# R7KA8P1AD register map
Vendor: Renesas Electronics Corporation; Series: RA8; File version: 1.10.02
CPU: CM85 r0p2, little endian, MPU, FPU, VTOR, 4 interrupt priority bits, 96 interrupts
Registers are 32-bit, read-write, reset 0x0 unless marked. A register's access mark holds for its fields unless they carry their own. Offsets are from the block's base; [hi:lo] are bit positions; {n}, {i} and the like mark numbered series; 'fields as' and 'values as' point back to an identical list.

## DRW — 2D Drawing Engine
Base 0x40444000
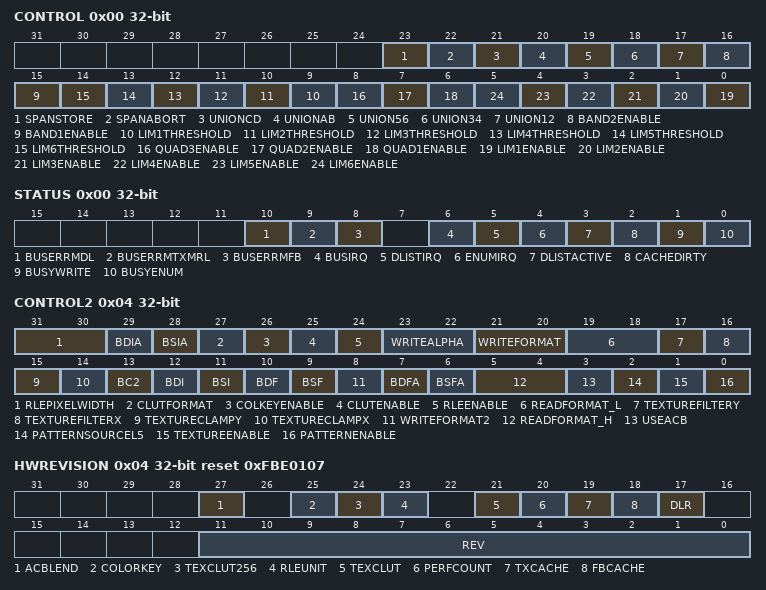
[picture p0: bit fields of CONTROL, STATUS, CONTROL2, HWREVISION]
0x00 CONTROL wo — Geometry Control Register
  [23] SPANSTORE
    0=Disable; 1=Enable. Next line span start is always equal to or left of the current line span start. See .
  [22] SPANABORT
    0=Disable; 1=Enable
  [21] UNIONCD — Combine Outputs C and D as Union
    0=Select minimum/intersect between limiters C and D; 1=Select maximum/union between limiters C and D. The output is final.
  [20] UNIONAB — Combine Outputs A and B as Union
    0=Select minimum/intersect between limiters A and B; 1=Select maximum/union between limiters A and B. The output is called C.
  [19] UNION56 — Combine Limiters 5 and 6 as Union
    0=Select minimum/intersect between limiters 5 and 6; 1=Select maximum/union between limiters 5 and 6. The output is called D.
  [18] UNION34 — Combine Limiters 3 and 4 as Union
    0=Select minimum/intersect between limiters 3 and 4; 1=Select maximum/union between limiters 3 and 4. The output is called B.
  [17] UNION12 — Combine Limiters 1 and 2 as Union
    0=Select minimum/intersect between limiters 1 and 2; 1=Select maximum/union between limiters 1 and 2. The output is called A.
  [16] BAND2ENABLE — Enable Band Post Process for Limiter 2
    0=Disable; 1=Enable
  [15] BAND1ENABLE — Enable Band Post Process for Limiter 1
    0=Disable; 1=Enable
  [n+8] LIM{n}THRESHOLD (n=1..6) — Enable Limiter {n} Threshold Mode
    0=Disable; 1=Enable
  [8] QUAD3ENABLE — Enable Quadratic Coupling of Limiters 5 and 6
    0=Disable; 1=Enable
  [7] QUAD2ENABLE — Enable Quadratic Coupling of Limiters 3 and 4
    0=Disable; 1=Enable
  [6] QUAD1ENABLE — Enable Quadratic Coupling of Limiters 1 and 2
    0=Disable; 1=Enable
  [n-1] LIM{n}ENABLE (n=1..6) — Enable Limiter {n}
    0=Disable; 1=Enable
0x00 STATUS ro (alternate view of CONTROL) — Status Control Register
  [10] BUSERRMDL — Display List Bus Error Interrupt Triggered
    0=No display list bus error occurred or interrupt disabled; 1=Display list bus error interrupt triggered
  [9] BUSERRMTXMRL — Texture Bus Error Interrupt Triggered
    0=No texture bus error occurred or interrupt disabled; 1=Texture bus error interrupt triggered
  [8] BUSERRMFB — Framebuffer Bus Error Interrupt Triggered
    0=No framebuffer bus error occurred or interrupt disabled; 1=Framebuffer bus error interrupt triggered
  [6] BUSIRQ — Bus Error Interrupt Triggered
    0=No bus error occurred or interrupt disabled; 1=Bus error interrupt triggered
  [5] DLISTIRQ — Display List Interrupt Triggered
    0=Display list not finished or interrupt disabled; 1=Display list finished interrupt triggered
  [4] ENUMIRQ — Enumeration Interrupt Triggered
    0=Enumeration not finished or interrupt disabled; 1=Enumeration finished interrupt triggered
  [3] DLISTACTIVE — Display List Reader Status
    0=Display list reader is idle; 1=Display list reader is busy, and no direct write access to registers allowed
  [2] CACHEDIRTY — Framebuffer Cache Status
    0=Framebuffer cache is not dirty; 1=Framebuffer cache is dirty, and frame should not be flipped
  [1] BUSYWRITE — Framebuffer Writeback Status
    0=Framebuffer writeback finished; 1=Framebuffer writeback busy, framebuffer type cannot be changed
  [0] BUSYENUM — Enumeration Unit Status
    0=Enumeration unit idle; 1=Enumeration unit is busy, new primitive cannot be started
0x04 CONTROL2 wo — Surface Control Register
  [31:30] RLEPIXELWIDTH — Texel Width for RLE Unit
    0=1 byte per texel; 1=2 bytes per texel; 2=3 bytes per texel; 3=4 bytes per texel
  [29] BDIA — Blend Destination Factor Inverted in Alpha Channel
    0=Use blend factor as specified through BDFA; 1=Invert destination blend factor (1-x)
  [28] BSIA — Blend Source Factor Inverted in Alpha Channel
    0=Use blend factor as specified through BSFA; 1=Invert blend source factor (1-x)
  [27] CLUTFORMAT
    0=Format CLUT as ARGB (8888); 1=Format CLUT as RGB (565)
  [26] COLKEYENABLE — Color Keying Enable
    0=Disable color keying; 1=Enable color keying
  [25] CLUTENABLE
    0=Disable CLUT; 1=Enable CLUT
  [24] RLEENABLE
    0=Disable RLE; 1=Enable RLE
  [23:22] WRITEALPHA — Writeback Alpha Source for Framebuffer
    0=(USEACB = 0) Use alpha from color 2 (USEACB = 0) (USEACB = 1) BC2A = 1: Use alpha in color 2 as destination (DST_A); 1=(USEACB = 0) Use source alpha (pixel coverage) (USEACB = 1) BC2A = 0: Use alpha from framebuffer as destination (DST_A); 2=(USEACB = 0) Use 0.0 as alpha (USEACB = 1) BC2A = 0: Use alpha from framebuffer as destination (DST_A); 2=(USEACB = 0) Use alpha from framebuffer (USEACB = 1) BC2A = 0: Use alpha from framebuffer as destination (DST_A)
  [21:20] WRITEFORMAT — Writeback Framebuffer Format
  [19:18] READFORMAT_L — Texture Format Descriptor
  [17] TEXTUREFILTERY — Linear Filtering on Texture V Axis
    0=No filtering on texture V axis; 1=Linear filtering on texture V axis
  [16] TEXTUREFILTERX — Linear Filtering on Texture U Axis
    0=No filtering on texture U axis; 1=Linear filtering on texture U axis
  [15] TEXTURECLAMPY — Calculating V Limiter Outside Used Texture
    0=Texture wrap mode: Integer part of the calculated value from the V limiter is AND gated with TEXVMASK, resulting in a repetition of texture in the y/v direction; 1=Texture clamp mode: Texture color at the border of the texture is taken, resulting in a repetition of texture border color in the y/v direction
  [14] TEXTURECLAMPX — Calculating U Limiter Outside Used Texture
    0=Texture wrap mode: Integer part of the calculated value from the U limiter is AND gated with TEXUMASK, resulting in a repetition of texture in the x/u direction; 1=Texture clamp mode: Texture color at the border of the texture is taken, resulting in a repetition of texture border color in the x/u direction
  [13] BC2 — Blend color 2
    0=Use pixel from framebuffer as destination (DST); 1=Use color 2 as destination (DST)
  [12] BDI — Blend Destination Factor Inverted
    0=Use blend factor as specified through BDF; 1=Invert blend destination factor (1-x)
  [11] BSI — Blend Source Factor Inverted
    0=Use blend factor as specified through BSF; 1=Invert blend source factor (1-x)
  [10] BDF — Blend Destination Factor
    0=Use 1.0 as blend destination factor; 1=Use alpha as blend destination factor
  [9] BSF — Blend Source Factor
    0=Use 1.0 as blend source factor; 1=Use alpha as blend source factor
  [8] WRITEFORMAT2 — Writeback Framebuffer Format
  [7] BDFA — Blend Destination Factor for Alpha Channel
    0=Use 1.0 as blend destination factor for alpha channel; 1=Use alpha as blend destination factor for alpha channel
  [6] BSFA — Blend Source Factor for Alpha Channel
    0=Use 1.0 as blend source factor for alpha channel; 1=Use alpha as blend source factor for alpha channel
  [5:4] READFORMAT_H — Texture Format Descriptor
  [3] USEACB — Alpha Blend Mode
    0=Use WRITEALPHA[1:0] mode; 1=Use full alpha channel blending mode
  [2] PATTERNSOURCEL5 — Limiter 5 Enable for Pattern Index
  [1] TEXTUREENABLE — Texture Enable for Pixel Source
    0=Disable texture; 1=Enable texture
  [0] PATTERNENABLE — Pattern Color Enable for Pixel Source
    0=Disable pattern; 1=Enable pattern
0x04 HWREVISION ro reset 0xFBE0107 (alternate view of CONTROL2) — Hardware Version and Feature Set ID Register
  [27] ACBLEND — Alpha Channel Blending Available
    0=Full alpha channel blending is not available; 1=Full alpha channel blending is available
  [25] COLORKEY — Color Key Available
    0=No color key; 1=Color key is available
  [24] TEXCLUT256 — Texture CLUT size
    0=Texture CLUT size is 16 entries; 1=Texture CLUT size is 256 entries
  [23] RLEUNIT — RLE Unit Available
    0=No RLE unit; 1=RLE unit is available
  [21] TEXCLUT — Texture CLUT Available
    0=No texture CLUT; 1=Texture CLUT is available
  [20] PERFCOUNT — Two Performance Counter Available
    0=No performance counter; 1=Tow performance counters available
  [19] TXCACHE — Texture Cache Available
    0=No texture cache; 1=Texture cache is available
  [18] FBCACHE — Framebuffer Cache Available
    0=No framebuffer cache; 1=Framebuffer cache is available
  [17] DLR — Display List Reader Available
    0=No display list reader; 1=Display list reader is available
  [11:0] REV — Revision Number of DRW is stored.
{0xC+4i} L{i}START (i=1..6) wo — Limiter {i} Start Value Register (n = 1 to 6)
  [31:0] LSTART — Start Value of the nth Limiter
{0x24+4i} L{i}XADD (i=1..6) wo — Limiter {i} X-Axis Increment Register(n = 1 to 6)
  [31:0] LXADD — X-Axis Increment
{0x3C+4i} L{i}YADD (i=1..6) wo — Limiter {i} Y-Axis Increment Register(n = 1 to 6)
  [31:0] LYADD — Y-Axis Increment
{0x54+4i} L{i}BAND (i=1..2) wo — Limiter m Band Width Parameter Register(n = 1, 2)
  [31:0] LBAND — Limiter m Band Width Parameter
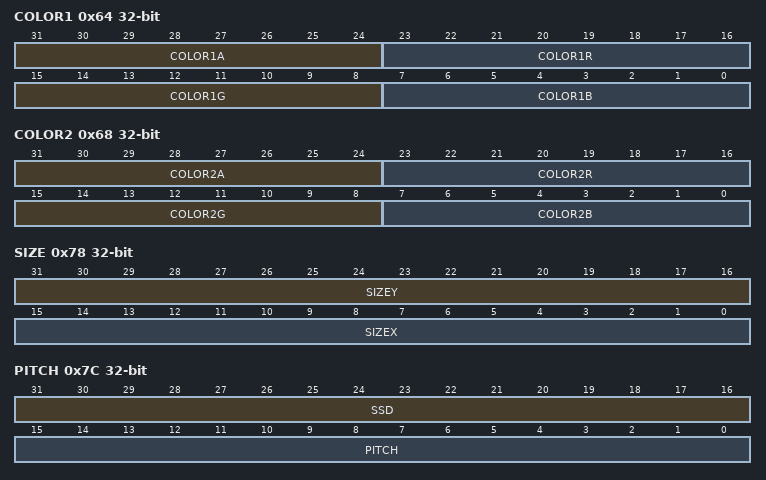
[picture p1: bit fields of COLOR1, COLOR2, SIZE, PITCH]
0x64 COLOR1 wo — Base Color Register
  [31:24] COLOR1A — Alpha Channel of Color 1
  [23:16] COLOR1R — Red Channel of Color 1
  [15:8] COLOR1G — Green Channel of Color 1
  [7:0] COLOR1B — Blue Channel of Color 1
0x68 COLOR2 wo — Secondary Color Register
  [31:24] COLOR2A — Alpha Channel of Color 2
  [23:16] COLOR2R — Red Channel of Color 2
  [15:8] COLOR2G — Green Channel of Color 2
  [7:0] COLOR2B — Blue Channel of Color 2
0x74 PATTERN wo
  [7:0] PATTERN — Bitmap of the Pattern
0x78 SIZE wo — Bounding Box Dimension Register
  [31:16] SIZEY — Bounding Box Height
  [15:0] SIZEX — Bounding Box Width
0x7C PITCH wo — Framebuffer Pitch And Spanstore Delay Register
  [31:16] SSD — Spanstore Delay
  [15:0] PITCH — Pitch of the Framebuffer
0x80 ORIGIN wo — Framebuffer Base Address Register
  [31:0] ORIGIN — Address of the First Pixel in Framebuffer
0x90 LUSTART wo — U Limiter Start Value Register
  [31:0] LUSTART — U Limiter Start Value
0x94 LUXADD wo — U Limiter X-Axis Increment Register
  [31:0] LUXADD — U Limiter X-Axis Increment
0x98 LUYADD wo — U Limiter Y-Axis Increment Register
  [31:0] LUYADD — U Limiter Y-Axis Increment
0x9C LVSTARTI wo — V Limiter Start Value Integer Part Register
  [0] LVSTARTI — V Limiter Start Value Integer Part
0xA0 LVSTARTF wo — V Limiter Start Value Fractional Part Register
  [15:0] LVSTARTF — V Limiter Start Value Fractional Part
0xA4 LVXADDI wo — V Limiter X-Axis Increment Integer Part Register
  [31:0] LVXADDI — V Limiter X-Axis Increment Integer Part
0xA8 LVYADDI wo — V Limiter Y-Axis Increment Integer Part Register
  [31:0] LVYADDI — V Limiter Y-Axis Increment Integer Part
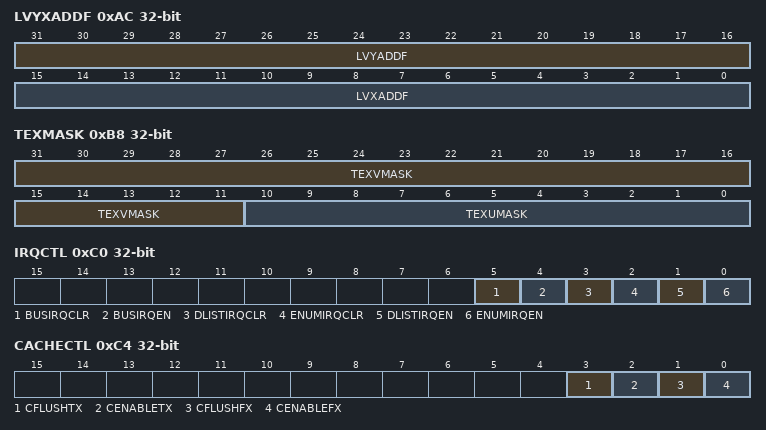
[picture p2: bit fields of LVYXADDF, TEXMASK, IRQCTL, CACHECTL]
0xAC LVYXADDF wo — V Limiter Increment Fractional Parts Register
  [31:16] LVYADDF — V Limiter Y-Axis Increment Fractional Part
  [15:0] LVXADDF — V Limiter X-Axis Increment Fractional Part
0xB4 TEXPITCH wo — Texels Per Texture Line Register
  [31:0] TEXPITCH — Texels Per Texture Line
0xB8 TEXMASK wo — Texture Size or Texture Address Mask Register
  [31:11] TEXVMASK — V Mask in Texture Mode
  [10:0] TEXUMASK — U Mask in Texture Mode
0xBC TEXORIGIN wo — Texture Base Address Register
  [31:0] TEXORIGIN — Texture Base Address
0xC0 IRQCTL wo — Interrupt Control Register
  [5] BUSIRQCLR — Clear BUSIRQ
    0=Do not clear BUSIRQ bus error interrupt; 1=Clear BUSIRQ bus error interrupt
  [4] BUSIRQEN — BUSIRQ Interrupt Mask Enable
    0=Disable (mask) BUSIRQ bus error interrupt; 1=Enable (unmask) BUSIRQ bus error interrupt
  [3] DLISTIRQCLR — Clear DLISTIRQ
    0=Do not clear DLISTIRQ display list interrupt; 1=Clear DLISTIRQ display list interrupt
  [2] ENUMIRQCLR — Clear ENUMIRQ
    0=Do not clear ENUMIRQ enumeration interrupt; 1=Clear ENUMIRQ enumeration interrupt
  [1] DLISTIRQEN — DLISTIRQ Interrupt Mask Enable
    0=Disable (mask) DLISTIRQ display list interrupt; 1=Enable (unmask) DLISTIRQ display list interrupt
  [0] ENUMIRQEN — ENUMIRQ Interrupt Mask Enable
    0=Disable (mask) ENUMIRQ enumeration interrupt; 1=Enable (unmask) ENUMIRQ enumeration interrupt
0xC4 CACHECTL wo — Cache Control Register
  [3] CFLUSHTX — Flush Texture Cache
    0=Do not flush the texture cache; 1=Flush the texture cache
  [2] CENABLETX — Texture Cache Enable
    0=Disable the texture cache; 1=Enable the texture cache
  [1] CFLUSHFX — Flush Framebuffer Cache
    0=Do not flush the framebuffer cache; 1=Flush the framebuffer cache
  [0] CENABLEFX — Framebuffer Cache Enable
    0=Disable the framebuffer cache; 1=Enable the framebuffer cache
0xC8 DLISTSTART wo — Display List Start Address Register
  [31:0] DLISTSTART — Display List Start Address
0xCC PERFCOUNT1 — Performance Counter 1
  [31:0] PERFCOUNT — Performance Counter k Value
0xD0 PERFCOUNT2 — Performance Counter 2
  [31:0] PERFCOUNT — Performance Counter k Value
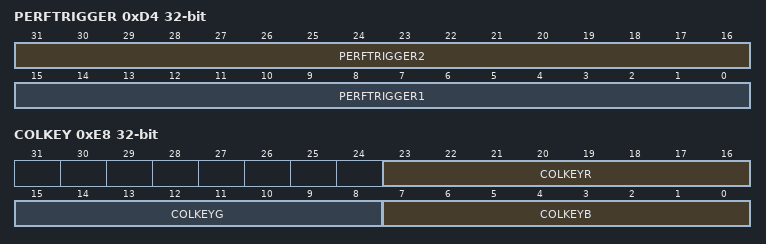
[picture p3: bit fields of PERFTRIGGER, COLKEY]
0xD4 PERFTRIGGER wo — Performance Counters Control Register
  [31:16] PERFTRIGGER2 — Trigger of Performance Counter 2
  [15:0] PERFTRIGGER1 — Trigger of Performance Counter 1
0xDC TEXCLADDR wo — CLUT Start Address Register
  [7:0] CLADDR — Texture CLUT Start Address
0xE0 TEXCLDATA wo — CLUT Data Register
  [31:0] CLDATA — Texture CLUT Data
0xE4 TEXCLOFFSET wo — CLUT Offset Register
  [7:0] CLOFFSET — Texture CLUT Offset
0xE8 COLKEY wo — Color Key Register
  [23:16] COLKEYR — Red Channel of Color Key
  [15:8] COLKEYG — Green Channel of Color Key
  [7:0] COLKEYB — Blue Channel of Color Key
0x100 DBWER — DRW Bufferable Write Enable Register
  [2] BWE — Bufferable Write Enable
    0=Disables Bufferable Write; 1=Enables Bufferable Write

## DRW_NS — 2D Drawing Engine
Base 0x50444000
Registers as DRW; these are added or differ:
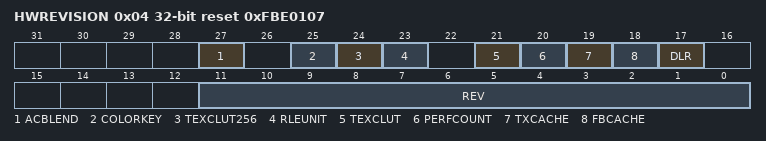
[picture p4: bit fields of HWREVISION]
0x04 HWREVISION ro reset 0xFBE0107 (alternate view of CONTROL2) — Hardware Version and Feature Set ID Register
  fields as DRW.HWREVISION
0x100 DBWER — DRW Bufferable Write Enable Register
  [2] BWE — Bufferable Write Enable
    0=Disables Bufferable Write; 1=Enables Bufferable Write
